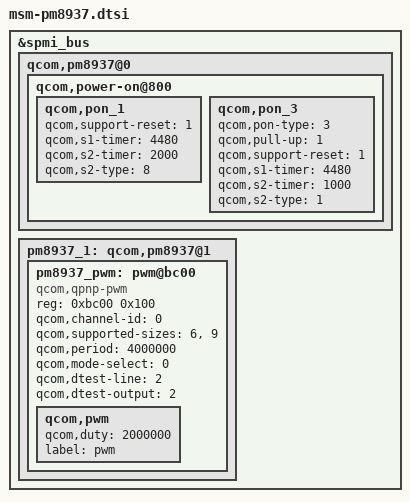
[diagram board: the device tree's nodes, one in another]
&spmi_bus {
	qcom,pm8937@0 {
		qcom,power-on@800 {
			qcom,pon_1 {
				qcom,support-reset = <1>;
				qcom,s1-timer = <4480>;
				qcom,s2-timer = <2000>;
				qcom,s2-type = <8>;
			};
			qcom,pon_3 {
				qcom,pon-type = <3>;
				qcom,pull-up = <1>;
				qcom,support-reset = <1>;
				qcom,s1-timer = <4480>;
				qcom,s2-timer = <1000>;
				qcom,s2-type = <1>;
			};
		};
	};
	pm8937_1: qcom,pm8937@1 {
		pm8937_pwm: pwm@bc00 {
		     compatible = "qcom,qpnp-pwm";
		     reg = <0xbc00 0x100>;
		     reg-names = "qpnp-lpg-channel-base";
		     qcom,channel-id = <0>;
		     qcom,supported-sizes = <6>,<9>;
		     qcom,period = <4000000>;
		     qcom,mode-select = <0>;
		     qcom,dtest-line = <2>;
		     qcom,dtest-output = <2>;
		     #pwm-cells = <2>;
		     status = "okay";

		     qcom,pwm {
			     qcom,duty = <2000000>;
			     label = "pwm";
		     };
		};
	};
};
